# CY8C5888LTI_LP097 register map
File version: 0.1
Registers are 8-bit, read-write, no defined reset value unless marked. A register's access mark holds for its fields unless they carry their own. Offsets are from the block's base; [hi:lo] are bit positions; 'fields as' and 'values as' point back to an identical list.

## PWM_RightMotor_2
Base 0x00000000
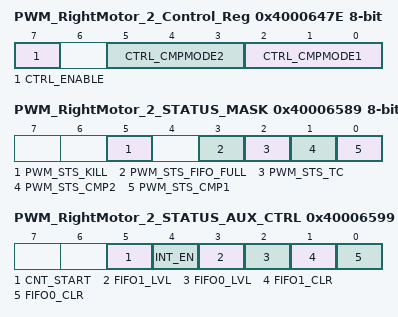
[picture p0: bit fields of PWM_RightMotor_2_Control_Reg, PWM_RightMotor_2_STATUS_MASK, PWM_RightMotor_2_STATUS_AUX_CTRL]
0x4000647E PWM_RightMotor_2_Control_Reg — UDB Control Register - Assigned Control Register Value
  [7] CTRL_ENABLE — Enable the PWM
  [5:3] CTRL_CMPMODE2 — Compare mode 2
  [2:0] CTRL_CMPMODE1 — Compare mode 1
0x40006529 PWM_RightMotor_2_COMPARE_Reg_ — UDB.D0 - Assigned Compare Value
0x40006589 PWM_RightMotor_2_STATUS_MASK — UDB Status bits Interrupt Mask Enable Register
  [5] PWM_STS_KILL ro — Enables the Interrupt on Kill
  [3] PWM_STS_FIFO_FULL ro — FIFO Full Status Mask
  [2] PWM_STS_TC ro — Enables the Interrupt on Terminal Count
  [1] PWM_STS_CMP2 ro — Enables the Interrupt on Compare 2
  [0] PWM_STS_CMP1 ro — Enables the Interrupt on Compare 1
0x40006599 PWM_RightMotor_2_STATUS_AUX_CTRL — UDB Auxilliary Control Register
  [5] CNT_START — FIFO0 clear
    0=E_CNT_START0 (Disable counter); 1=E_CNT_START1 (Enable counter)
  [4] INT_EN
    0=E_INT_EN0 (Interrupt disabled); 1=E_INT_EN1 (Interrupt enabled)
  [3] FIFO1_LVL — FIFO level
    0=E_FIFO_LVL_0 (FIFO LVL: input mode: FIFO not full; output mode: FIFO not empty); 1=E_FIFO_LVL_1 (FIFO LVL: input mode: FIFO at least 1/2 empty; output mode: FIFO at least 1/2 full)
  [2] FIFO0_LVL — FIFO level
    values as FIFO1_LVL
  [1] FIFO1_CLR — FIFO1 clear
    0=E_FIFO_CLR_0 (Normal FIFO operation); 1=E_FIFO_CLR_1 (Clear FIFO state)
  [0] FIFO0_CLR — FIFO0 clear
    values as FIFO1_CLR

## PWM_LeftMotor_2
Base 0x00000000
0x4000652A PWM_LeftMotor_2_COMPARE_Reg_ — UDB.D0 - Assigned Compare Value
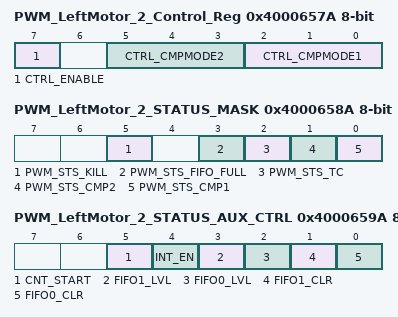
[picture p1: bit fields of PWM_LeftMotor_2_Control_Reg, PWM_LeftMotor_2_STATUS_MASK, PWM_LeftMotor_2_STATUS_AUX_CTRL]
0x4000657A PWM_LeftMotor_2_Control_Reg — UDB Control Register - Assigned Control Register Value
  [7] CTRL_ENABLE — Enable the PWM
  [5:3] CTRL_CMPMODE2 — Compare mode 2
  [2:0] CTRL_CMPMODE1 — Compare mode 1
0x4000658A PWM_LeftMotor_2_STATUS_MASK — UDB Status bits Interrupt Mask Enable Register
  [5] PWM_STS_KILL ro — Enables the Interrupt on Kill
  [3] PWM_STS_FIFO_FULL ro — FIFO Full Status Mask
  [2] PWM_STS_TC ro — Enables the Interrupt on Terminal Count
  [1] PWM_STS_CMP2 ro — Enables the Interrupt on Compare 2
  [0] PWM_STS_CMP1 ro — Enables the Interrupt on Compare 1
0x4000659A PWM_LeftMotor_2_STATUS_AUX_CTRL — UDB Auxilliary Control Register
  [5] CNT_START — FIFO0 clear
    0=E_CNT_START0 (Disable counter); 1=E_CNT_START1 (Enable counter)
  [4] INT_EN
    0=E_INT_EN0 (Interrupt disabled); 1=E_INT_EN1 (Interrupt enabled)
  [3] FIFO1_LVL — FIFO level
    0=E_FIFO_LVL_0 (FIFO LVL: input mode: FIFO not full; output mode: FIFO not empty); 1=E_FIFO_LVL_1 (FIFO LVL: input mode: FIFO at least 1/2 empty; output mode: FIFO at least 1/2 full)
  [2] FIFO0_LVL — FIFO level
    values as FIFO1_LVL
  [1] FIFO1_CLR — FIFO1 clear
    0=E_FIFO_CLR_0 (Normal FIFO operation); 1=E_FIFO_CLR_1 (Clear FIFO state)
  [0] FIFO0_CLR — FIFO0 clear
    values as FIFO1_CLR

## UART
Base 0x00000000
0x4000642B RX_UART_RX_ADDRESS1 — RX Address1 Register
0x4000643B RX_UART_RX_ADDRESS2 — RX Address2 Register
0x40006447 TX_UART_TX_DATA — TX Data Register
0x4000644B RX_UART_RX_DATA — RX Data Register
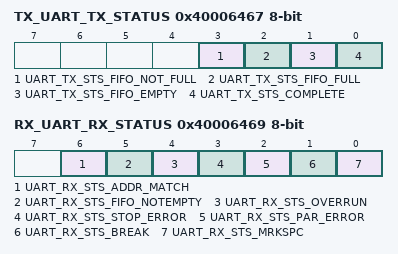
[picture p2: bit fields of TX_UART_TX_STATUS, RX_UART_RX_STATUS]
0x40006467 TX_UART_TX_STATUS — TX status register
  [3] UART_TX_STS_FIFO_NOT_FULL ro, [2] UART_TX_STS_FIFO_FULL ro, [1] UART_TX_STS_FIFO_EMPTY ro, [0] UART_TX_STS_COMPLETE ro
0x40006469 RX_UART_RX_STATUS — RX status register
  [6] UART_RX_STS_ADDR_MATCH ro, [5] UART_RX_STS_FIFO_NOTEMPTY ro, [4] UART_RX_STS_OVERRUN ro, [3] UART_RX_STS_STOP_ERROR ro, [2] UART_RX_STS_PAR_ERROR ro, [1] UART_RX_STS_BREAK ro, [0] UART_RX_STS_MRKSPC ro

## PWM_LeftMotor_1
Base 0x00000000
0x40006526 PWM_LeftMotor_1_COMPARE_Reg_ — UDB.D0 - Assigned Compare Value
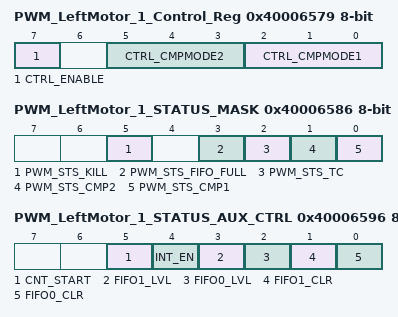
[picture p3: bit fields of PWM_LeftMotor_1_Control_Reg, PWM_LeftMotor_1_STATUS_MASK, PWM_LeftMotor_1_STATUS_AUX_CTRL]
0x40006579 PWM_LeftMotor_1_Control_Reg — UDB Control Register - Assigned Control Register Value
  [7] CTRL_ENABLE — Enable the PWM
  [5:3] CTRL_CMPMODE2 — Compare mode 2
  [2:0] CTRL_CMPMODE1 — Compare mode 1
0x40006586 PWM_LeftMotor_1_STATUS_MASK — UDB Status bits Interrupt Mask Enable Register
  [5] PWM_STS_KILL ro — Enables the Interrupt on Kill
  [3] PWM_STS_FIFO_FULL ro — FIFO Full Status Mask
  [2] PWM_STS_TC ro — Enables the Interrupt on Terminal Count
  [1] PWM_STS_CMP2 ro — Enables the Interrupt on Compare 2
  [0] PWM_STS_CMP1 ro — Enables the Interrupt on Compare 1
0x40006596 PWM_LeftMotor_1_STATUS_AUX_CTRL — UDB Auxilliary Control Register
  [5] CNT_START — FIFO0 clear
    0=E_CNT_START0 (Disable counter); 1=E_CNT_START1 (Enable counter)
  [4] INT_EN
    0=E_INT_EN0 (Interrupt disabled); 1=E_INT_EN1 (Interrupt enabled)
  [3] FIFO1_LVL — FIFO level
    0=E_FIFO_LVL_0 (FIFO LVL: input mode: FIFO not full; output mode: FIFO not empty); 1=E_FIFO_LVL_1 (FIFO LVL: input mode: FIFO at least 1/2 empty; output mode: FIFO at least 1/2 full)
  [2] FIFO0_LVL — FIFO level
    values as FIFO1_LVL
  [1] FIFO1_CLR — FIFO1 clear
    0=E_FIFO_CLR_0 (Normal FIFO operation); 1=E_FIFO_CLR_1 (Clear FIFO state)
  [0] FIFO0_CLR — FIFO0 clear
    values as FIFO1_CLR

## Timer_Left
Base 0x00000000
0x40006507 Timer_Left_COUNTER 16-bit — UDB.A0 - Current Down Counter Value
0x40006527 Timer_Left_PERIOD 16-bit — UDB.D0 - Assigned Period
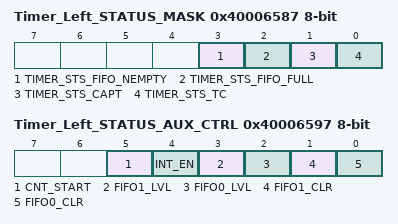
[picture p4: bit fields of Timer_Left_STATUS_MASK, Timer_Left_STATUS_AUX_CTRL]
0x40006587 Timer_Left_STATUS_MASK — UDB Status bits Interrupt Mask Enable Register
  [3] TIMER_STS_FIFO_NEMPTY ro — FIFO Empty status
  [2] TIMER_STS_FIFO_FULL ro — FIFO Full Status
  [1] TIMER_STS_CAPT ro — Enables the Interrupt on Capture
  [0] TIMER_STS_TC ro — Enables the Interrupt on TC
0x40006597 Timer_Left_STATUS_AUX_CTRL — UDB Auxilliary Control Register
  [5] CNT_START — FIFO0 clear
    0=E_CNT_START0 (Disable counter); 1=E_CNT_START1 (Enable counter)
  [4] INT_EN
    0=E_INT_EN0 (Interrupt disabled); 1=E_INT_EN1 (Interrupt enabled)
  [3] FIFO1_LVL — FIFO level
    0=E_FIFO_LVL_0 (FIFO LVL: input mode: FIFO not full; output mode: FIFO not empty); 1=E_FIFO_LVL_1 (FIFO LVL: input mode: FIFO at least 1/2 empty; output mode: FIFO at least 1/2 full)
  [2] FIFO0_LVL — FIFO level
    values as FIFO1_LVL
  [1] FIFO1_CLR — FIFO1 clear
    0=E_FIFO_CLR_0 (Normal FIFO operation); 1=E_FIFO_CLR_1 (Clear FIFO state)
  [0] FIFO0_CLR — FIFO0 clear
    values as FIFO1_CLR

## Timer_Front_Left
Base 0x00000000
0x4000640C Timer_Front_Left_COUNTER 16-bit — UDB.A0 - Current Down Counter Value
0x4000642C Timer_Front_Left_PERIOD 16-bit — UDB.D0 - Assigned Period
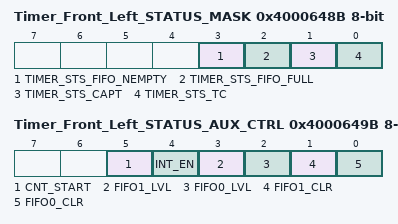
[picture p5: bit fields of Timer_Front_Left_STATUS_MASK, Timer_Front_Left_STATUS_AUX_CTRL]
0x4000648B Timer_Front_Left_STATUS_MASK — UDB Status bits Interrupt Mask Enable Register
  [3] TIMER_STS_FIFO_NEMPTY ro — FIFO Empty status
  [2] TIMER_STS_FIFO_FULL ro — FIFO Full Status
  [1] TIMER_STS_CAPT ro — Enables the Interrupt on Capture
  [0] TIMER_STS_TC ro — Enables the Interrupt on TC
0x4000649B Timer_Front_Left_STATUS_AUX_CTRL — UDB Auxilliary Control Register
  [5] CNT_START — FIFO0 clear
    0=E_CNT_START0 (Disable counter); 1=E_CNT_START1 (Enable counter)
  [4] INT_EN
    0=E_INT_EN0 (Interrupt disabled); 1=E_INT_EN1 (Interrupt enabled)
  [3] FIFO1_LVL — FIFO level
    0=E_FIFO_LVL_0 (FIFO LVL: input mode: FIFO not full; output mode: FIFO not empty); 1=E_FIFO_LVL_1 (FIFO LVL: input mode: FIFO at least 1/2 empty; output mode: FIFO at least 1/2 full)
  [2] FIFO0_LVL — FIFO level
    values as FIFO1_LVL
  [1] FIFO1_CLR — FIFO1 clear
    0=E_FIFO_CLR_0 (Normal FIFO operation); 1=E_FIFO_CLR_1 (Clear FIFO state)
  [0] FIFO0_CLR — FIFO0 clear
    values as FIFO1_CLR

## Timer_Front_Right
Base 0x00000000
0x4000640E Timer_Front_Right_COUNTER 16-bit — UDB.A0 - Current Down Counter Value
0x4000642E Timer_Front_Right_PERIOD 16-bit — UDB.D0 - Assigned Period
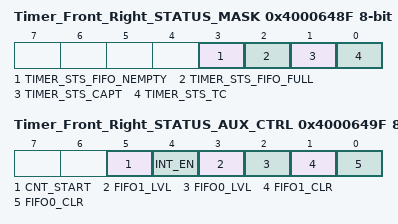
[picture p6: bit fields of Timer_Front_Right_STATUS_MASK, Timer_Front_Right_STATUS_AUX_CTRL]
0x4000648F Timer_Front_Right_STATUS_MASK — UDB Status bits Interrupt Mask Enable Register
  [3] TIMER_STS_FIFO_NEMPTY ro — FIFO Empty status
  [2] TIMER_STS_FIFO_FULL ro — FIFO Full Status
  [1] TIMER_STS_CAPT ro — Enables the Interrupt on Capture
  [0] TIMER_STS_TC ro — Enables the Interrupt on TC
0x4000649F Timer_Front_Right_STATUS_AUX_CTRL — UDB Auxilliary Control Register
  [5] CNT_START — FIFO0 clear
    0=E_CNT_START0 (Disable counter); 1=E_CNT_START1 (Enable counter)
  [4] INT_EN
    0=E_INT_EN0 (Interrupt disabled); 1=E_INT_EN1 (Interrupt enabled)
  [3] FIFO1_LVL — FIFO level
    0=E_FIFO_LVL_0 (FIFO LVL: input mode: FIFO not full; output mode: FIFO not empty); 1=E_FIFO_LVL_1 (FIFO LVL: input mode: FIFO at least 1/2 empty; output mode: FIFO at least 1/2 full)
  [2] FIFO0_LVL — FIFO level
    values as FIFO1_LVL
  [1] FIFO1_CLR — FIFO1 clear
    0=E_FIFO_CLR_0 (Normal FIFO operation); 1=E_FIFO_CLR_1 (Clear FIFO state)
  [0] FIFO0_CLR — FIFO0 clear
    values as FIFO1_CLR
